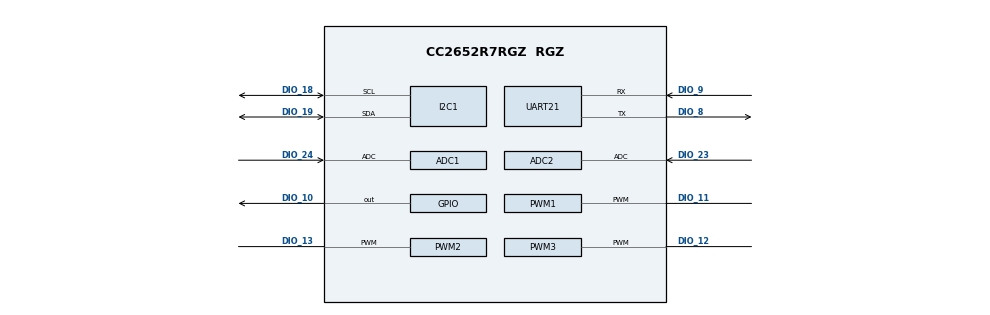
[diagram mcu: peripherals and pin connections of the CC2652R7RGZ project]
/**
 * @cliArgs --device "CC2652R7RGZ" --package "RGZ" --part "Default" --rtos "tirtos7" --product "simplelink_cc13xx_cc26xx_sdk@7.40.00.77"
 * @versions {"tool":"1.18.1+3343"}
 */

/**
 * Import the modules used in this configuration.
 */
const ble          = scripting.addModule("/ti/ble5stack/ble");
const CCFG         = scripting.addModule("/ti/devices/CCFG");
const rfdesign     = scripting.addModule("/ti/devices/radioconfig/rfdesign");
const ADC          = scripting.addModule("/ti/drivers/ADC", {}, false);
const ADC1         = ADC.addInstance();
const ADC2         = ADC.addInstance();
const AESCCM       = scripting.addModule("/ti/drivers/AESCCM");
const AESCCM1      = AESCCM.addInstance();
const AESCTRDRBG   = scripting.addModule("/ti/drivers/AESCTRDRBG");
const AESCTRDRBG1  = AESCTRDRBG.addInstance();
const AESECB       = scripting.addModule("/ti/drivers/AESECB");
const AESECB1      = AESECB.addInstance();
const ECDH         = scripting.addModule("/ti/drivers/ECDH");
const ECDH1        = ECDH.addInstance();
const GPIO         = scripting.addModule("/ti/drivers/GPIO");
const GPIO3        = GPIO.addInstance();
const I2C          = scripting.addModule("/ti/drivers/I2C", {}, false);
const I2C1         = I2C.addInstance();
const NVS          = scripting.addModule("/ti/drivers/NVS");
const NVS1         = NVS.addInstance();
const PWM          = scripting.addModule("/ti/drivers/PWM", {}, false);
const PWM1         = PWM.addInstance();
const PWM2         = PWM.addInstance();
const PWM3         = PWM.addInstance();
const Power        = scripting.addModule("/ti/drivers/Power");
const RF           = scripting.addModule("/ti/drivers/RF");
const TRNG         = scripting.addModule("/ti/drivers/TRNG");
const TRNG1        = TRNG.addInstance();
const UART2        = scripting.addModule("/ti/drivers/UART2", {}, false);
const UART21       = UART2.addInstance();
const Settings     = scripting.addModule("/ti/posix/tirtos/Settings");
const BIOS         = scripting.addModule("/ti/sysbios/BIOS");
const GateMutexPri = scripting.addModule("/ti/sysbios/gates/GateMutexPri");
const HeapCallback = scripting.addModule("/ti/sysbios/heaps/HeapCallback");
const Event        = scripting.addModule("/ti/sysbios/knl/Event");
const Idle         = scripting.addModule("/ti/sysbios/knl/Idle", {}, false);
const Idle2        = Idle.addInstance();
const Mailbox      = scripting.addModule("/ti/sysbios/knl/Mailbox");
const Error        = scripting.addModule("/ti/sysbios/runtime/Error");
const SysCallback  = scripting.addModule("/ti/sysbios/runtime/SysCallback");
const Timestamp    = scripting.addModule("/ti/sysbios/runtime/Timestamp");

/**
 * Write custom configuration values to the imported modules.
 */
ble.lockProject                                           = true;
ble.bondIOCaps                                            = "GAPBOND_IO_CAP_NO_INPUT_NO_OUTPUT";
ble.maxBonds                                              = 4;
ble.numOfAdvSets                                          = 1;
ble.deviceName                                            = "Genev gGo ES01";
ble.maxConnNum                                            = 1;
ble.maxPDUNum                                             = 25;
ble.rpaRead                                               = 750;
ble.radioConfig.codeExportConfig.$name                    = "ti_devices_radioconfig_code_export_param0";
ble.connUpdateParamsPeripheral.$name                      = "ti_ble5stack_general_ble_conn_update_params0";
ble.advSet1.$name                                         = "ti_ble5stack_broadcaster_advertisement_set0";
ble.advSet1.advParam1.$name                               = "ti_ble5stack_broadcaster_advertisement_params0";
ble.advSet1.advData1.$name                                = "ti_ble5stack_broadcaster_advertisement_data0";
ble.advSet1.advData1.GAP_ADTYPE_FLAGS                     = true;
ble.advSet1.advData1.GAP_ADTYPE_LOCAL_NAME_SHORT          = true;
ble.advSet1.advData1.GAP_ADTYPE_16BIT_MORE                = true;
ble.advSet1.advData1.numOfUUIDs16More                     = 1;
ble.advSet1.advData1.UUID016More                          = 0xFFF0;
ble.advSet1.advData1.shortenedLocalName                   = "gGo";
ble.advSet1.advData1.GAP_ADTYPE_ADV_INTERVAL              = true;
ble.advSet1.advData1.advertisingFlags                     = ["GAP_ADTYPE_FLAGS_BREDR_NOT_SUPPORTED","GAP_ADTYPE_FLAGS_LIMITED"];
ble.advSet1.scanRes1.$name                                = "ti_ble5stack_broadcaster_advertisement_data1";
ble.advSet1.scanRes1.GAP_ADTYPE_LOCAL_NAME_COMPLETE       = true;
ble.advSet1.scanRes1.GAP_ADTYPE_SLAVE_CONN_INTERVAL_RANGE = true;
ble.advSet1.scanRes1.maxConnInterval                      = 130;
ble.advSet1.scanRes1.GAP_ADTYPE_POWER_LEVEL               = true;
scripting.suppress("The example app code handles 2 advertisement sets\\. Please make sure to update the example app code according to the configured number of sets\\.", ble, "numOfAdvSets");

CCFG.enableBootloader         = true;
CCFG.enableBootloaderBackdoor = true;
CCFG.levelBootloaderBackdoor  = "Active low";
CCFG.dioBootloaderBackdoor    = 25;
CCFG.ccfgTemplate.$name       = "ti_devices_CCFG_CCFGCC26XXTemplate0";

ADC1.$name              = "CONFIG_ADC_THR";
ADC1.adc.$assign        = "ADC0";
ADC1.adc.adcPin.$assign = "DIO_24";

ADC2.$name              = "CONFIG_ADC_BRK";
ADC2.adc.$assign        = "ADC0";
ADC2.adc.adcPin.$assign = "DIO_23";

AESCCM1.$name = "CONFIG_AESCCM0";

AESCTRDRBG1.$name = "CONFIG_AESCTRDRBG_0";

AESECB1.$name = "CONFIG_AESECB0";

ECDH1.$name = "CONFIG_ECDH0";

GPIO3.$name            = "CONFIG_GPIO_MPB";
GPIO3.interruptTrigger = "Both Edges";
GPIO3.gpioPin.$assign  = "DIO_10";

I2C1.$name              = "CONFIG_I2C";
I2C1.i2c.$assign        = "I2C0";
I2C1.i2c.sdaPin.$assign = "DIO_19";
I2C1.i2c.sclPin.$assign = "DIO_18";

NVS1.$name                    = "CONFIG_NVSINTERNAL";
NVS1.internalFlash.$name      = "ti_drivers_nvs_NVSCC26XX0";
NVS1.internalFlash.regionBase = 0x48000;
NVS1.internalFlash.regionSize = 0x4000;

PWM1.$name                            = "CONFIG_PWM_HEADLIGHT";
PWM1.timerObject.$name                = "CONFIG_GPTIMER_0";
PWM1.timerObject.timer.$assign        = "GPTM0";
PWM1.timerObject.timer.pwmPin.$assign = "DIO_11";

PWM2.$name                            = "CONFIG_PWM_BUZZER";
PWM2.timerObject.$name                = "CONFIG_GPTIMER_1";
PWM2.timerObject.timer.$assign        = "GPTM0";
PWM2.timerObject.timer.pwmPin.$assign = "DIO_13";

PWM3.$name                            = "CONFIG_PWM_LIGHT1";
PWM3.timerObject.$name                = "CONFIG_GPTIMER_2";
PWM3.timerObject.timer.$assign        = "GPTM1";
PWM3.timerObject.timer.pwmPin.$assign = "DIO_12";

TRNG1.$name = "CONFIG_TRNG_0";

UART21.$name              = "CONFIG_UART2_1";
UART21.uart.$assign       = "UART1";
UART21.uart.txPin.$assign = "DIO_8";
UART21.uart.rxPin.$assign = "DIO_9";

BIOS.assertsEnabled = false;
BIOS.rtsGateType    = "BIOS_GateMutexPri";
BIOS.heapSize       = 0x00000000;
BIOS.heapType       = "HeapCallback";

HeapCallback.initFxn           = "osalHeapInitFxn";
HeapCallback.allocInstFxn      = "osalHeapAllocFxn";
HeapCallback.freeInstFxn       = "osalHeapFreeFxn";
HeapCallback.getStatsInstFxn   = "osalHeapGetStatsFxn";
HeapCallback.isBlockingInstFxn = "osalHeapIsBlockingFxn";

const Clock       = scripting.addModule("/ti/sysbios/knl/Clock", {}, false);
Clock.tickPeriod  = 10;
Clock.swiPriority = 5;

const Timer       = scripting.addModule("/ti/sysbios/family/arm/cc26xx/Timer", {}, false);
Timer.rtc.$assign = "RTC0";

Idle2.$name   = "powerIdle";
Idle2.idleFxn = "Power_idleFunc";

const Semaphore            = scripting.addModule("/ti/sysbios/knl/Semaphore", {}, false);
Semaphore.supportsPriority = false;

const Swi         = scripting.addModule("/ti/sysbios/knl/Swi", {}, false);
Swi.numPriorities = 6;

const Task             = scripting.addModule("/ti/sysbios/knl/Task", {}, false);
Task.defaultStackSize  = 512;
Task.idleTaskStackSize = 768;
Task.numPriorities     = 6;

Error.policy       = "Error_SPIN";
Error.printDetails = false;

const System           = scripting.addModule("/ti/sysbios/runtime/System", {}, false);
System.abortFxn        = "System_abortSpin";
System.exitFxn         = "System_exitSpin";
System.extendedFormats = "%f";
System.supportModule   = "SysCallback";
